# sys_aes register map
Registers are read-write, no defined reset value unless marked. A register's access mark holds for its fields unless they carry their own. Offsets are from the block's base; lines under a group give offsets from that group; [hi:lo] are bit positions; {n}, {i} and the like mark numbered series; 'fields as' and 'values as' point back to an identical list; <NAME> marks a mode.

## Memory map
0x40007400 SYS_AES size 0x800 — AES Keys.

## SYS_AES — AES Keys.
Base 0x40007400
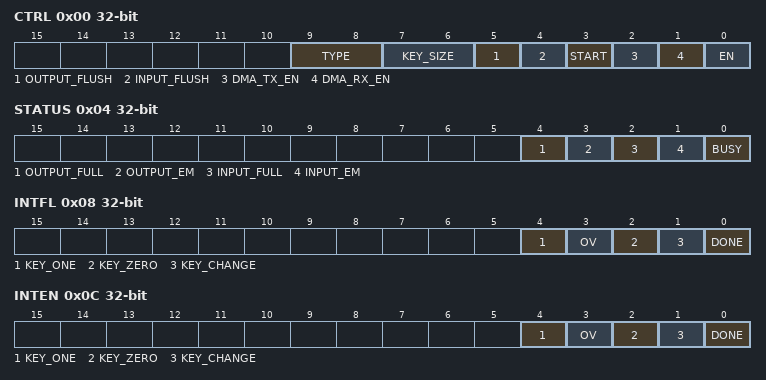
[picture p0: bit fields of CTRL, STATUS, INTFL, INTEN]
0x00 CTRL 32-bit — AES Control Register
  [9:8] TYPE — Encryption Type Selection
  [7:6] KEY_SIZE — Encryption Key Size
    0=AES128 (128 Bits.); 1=AES192 (192 Bits.); 2=AES256 (256 Bits.)
  [5] OUTPUT_FLUSH — Flush the data output FIFO
  [4] INPUT_FLUSH — Flush the data input FIFO
  [3] START — Start AES Calculation
  [2] DMA_TX_EN — DMA Request To Write Data Input FIFO
  [1] DMA_RX_EN — DMA Request To Read Data Output FIFO
  [0] EN — AES Enable
0x04 STATUS — AES Status Register
  [4] OUTPUT_FULL — Data output FIFO full status
  [3] OUTPUT_EM — Data output FIFO empty status
  [2] INPUT_FULL — Data input FIFO full status
  [1] INPUT_EM — Data input FIFO empty status
  [0] BUSY — AES Busy Status
0x08 INTFL — AES Interrupt Flag Register
  [4] KEY_ONE
  [3] OV — Data Output FIFO Overrun Interrupt
  [2] KEY_ZERO — External AES Key Zero Interrupt
  [1] KEY_CHANGE — External AES Key Changed Interrupt
  [0] DONE — AES Done Interrupt
0x0C INTEN — AES Interrupt Enable Register
  [4] KEY_ONE
  [3] OV — Data Output FIFO Overrun Interrupt Enable
  [2] KEY_ZERO — External AES Key Zero Interrupt Enable
  [1] KEY_CHANGE — External AES Key Changed Interrupt Enable
  [0] DONE — AES Done Interrupt Enable
0x10 FIFO — AES Data Register
  [0] DATA — AES FIFO
